# EFM32GG232F1024 register map
File version: 4.0.0
CPU: CM3 r2p1, little endian, MPU, no FPU, 3 interrupt priority bits
Registers are 32-bit, read-write, reset 0x0 unless marked. A register's access mark holds for its fields unless they carry their own. Offsets are from the block's base; [hi:lo] are bit positions; {n}, {i} and the like mark numbered series; 'fields as' and 'values as' point back to an identical list.

## GPIO
Base 0x40006000
0x00 PA_CTRL — Port Control Register
  [1:0] DRIVEMODE — Drive Mode Select
    0=STANDARD (6 mA drive current); 1=LOWEST (0.1 mA drive current); 2=HIGH (20 mA drive current); 3=LOW (1 mA drive current)
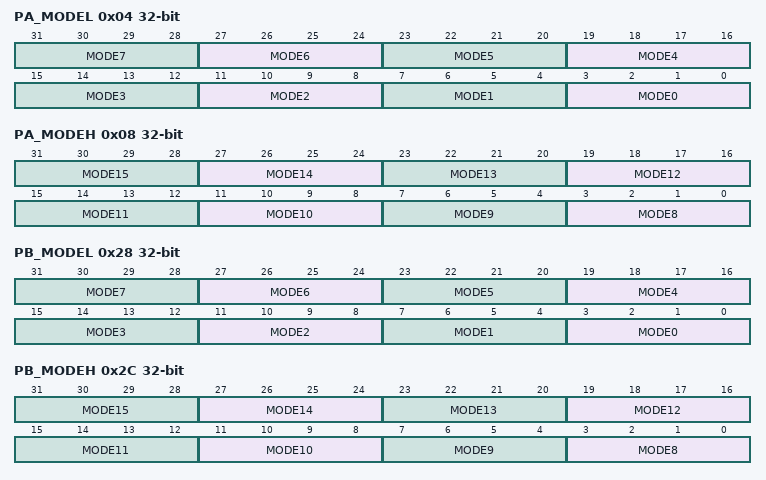
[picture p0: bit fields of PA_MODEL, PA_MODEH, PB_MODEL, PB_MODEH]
0x04 PA_MODEL — Port Pin Mode Low Register
  [all] fields
    0=DISABLED (Input disabled. Pullup if DOUT is set.); 1=INPUT (Input enabled. Filter if DOUT is set); 2=INPUTPULL (Input enabled. DOUT determines pull direction); 3=INPUTPULLFILTER (Input enabled with filter. DOUT determines pull direction); 4=PUSHPULL (Push-pull output); 5=PUSHPULLDRIVE (Push-pull output with drive-strength set by DRIVEMODE); 6=WIREDOR (Wired-or output); 7=WIREDORPULLDOWN (Wired-or output with pull-down); 8=WIREDAND (Open-drain output); 9=WIREDANDFILTER (Open-drain output with filter); 10=WIREDANDPULLUP (Open-drain output with pullup); 11=WIREDANDPULLUPFILTER (Open-drain output with filter and pullup); 12=WIREDANDDRIVE (Open-drain output with drive-strength set by DRIVEMODE); 13=WIREDANDDRIVEFILTER (Open-drain output with filter and drive-strength set by DRIVEMODE); 14=WIREDANDDRIVEPULLUP (Open-drain output with pullup and drive-strength set by DRIVEMODE); 15=WIREDANDDRIVEPULLUPFILTER (Open-drain output with filter, pullup and drive-strength set by DRIVEMODE)
  [4n+3:4n] MODE{n} (n=0..7) — Pin {n} Mode
0x08 PA_MODEH — Port Pin Mode High Register
  [all] fields
    values as the fields of PA_MODEL
  [4n-29:4n-32] MODE{n} (n=8..15) — Pin {n} Mode
0x0C PA_DOUT — Port Data Out Register
  [15:0] DOUT — Data Out
0x10 PA_DOUTSET wo — Port Data Out Set Register
  [15:0] DOUTSET — Data Out Set
0x14 PA_DOUTCLR wo — Port Data Out Clear Register
  [15:0] DOUTCLR — Data Out Clear
0x18 PA_DOUTTGL wo — Port Data Out Toggle Register
  [15:0] DOUTTGL — Data Out Toggle
0x1C PA_DIN ro — Port Data In Register
  [15:0] DIN — Data In
0x20 PA_PINLOCKN reset 0xFFFF — Port Unlocked Pins Register
  [15:0] PINLOCKN — Unlocked Pins
0x24 PB_CTRL — Port Control Register
  fields as PA_CTRL
0x28 PB_MODEL — Port Pin Mode Low Register
  fields as PA_MODEL
0x2C PB_MODEH — Port Pin Mode High Register
  fields as PA_MODEH
0x30 PB_DOUT — Port Data Out Register
  [15:0] DOUT — Data Out
0x34 PB_DOUTSET wo — Port Data Out Set Register
  [15:0] DOUTSET — Data Out Set
0x38 PB_DOUTCLR wo — Port Data Out Clear Register
  [15:0] DOUTCLR — Data Out Clear
0x3C PB_DOUTTGL wo — Port Data Out Toggle Register
  [15:0] DOUTTGL — Data Out Toggle
0x40 PB_DIN ro — Port Data In Register
  [15:0] DIN — Data In
0x44 PB_PINLOCKN reset 0xFFFF — Port Unlocked Pins Register
  [15:0] PINLOCKN — Unlocked Pins
0x48 PC_CTRL — Port Control Register
  fields as PA_CTRL
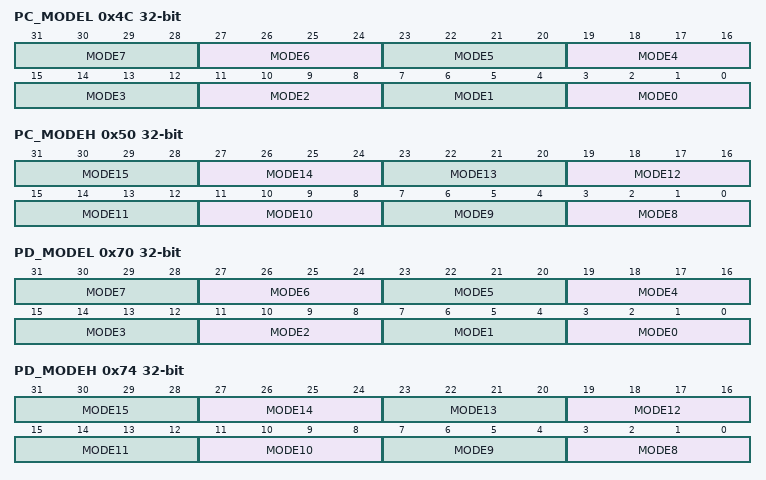
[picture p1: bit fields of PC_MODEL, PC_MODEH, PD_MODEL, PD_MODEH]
0x4C PC_MODEL — Port Pin Mode Low Register
  fields as PA_MODEL
0x50 PC_MODEH — Port Pin Mode High Register
  fields as PA_MODEH
0x54 PC_DOUT — Port Data Out Register
  [15:0] DOUT — Data Out
0x58 PC_DOUTSET wo — Port Data Out Set Register
  [15:0] DOUTSET — Data Out Set
0x5C PC_DOUTCLR wo — Port Data Out Clear Register
  [15:0] DOUTCLR — Data Out Clear
0x60 PC_DOUTTGL wo — Port Data Out Toggle Register
  [15:0] DOUTTGL — Data Out Toggle
0x64 PC_DIN ro — Port Data In Register
  [15:0] DIN — Data In
0x68 PC_PINLOCKN reset 0xFFFF — Port Unlocked Pins Register
  [15:0] PINLOCKN — Unlocked Pins
0x6C PD_CTRL — Port Control Register
  fields as PA_CTRL
0x70 PD_MODEL — Port Pin Mode Low Register
  fields as PA_MODEL
0x74 PD_MODEH — Port Pin Mode High Register
  fields as PA_MODEH
0x78 PD_DOUT — Port Data Out Register
  [15:0] DOUT — Data Out
0x7C PD_DOUTSET wo — Port Data Out Set Register
  [15:0] DOUTSET — Data Out Set
0x80 PD_DOUTCLR wo — Port Data Out Clear Register
  [15:0] DOUTCLR — Data Out Clear
0x84 PD_DOUTTGL wo — Port Data Out Toggle Register
  [15:0] DOUTTGL — Data Out Toggle
0x88 PD_DIN ro — Port Data In Register
  [15:0] DIN — Data In
0x8C PD_PINLOCKN reset 0xFFFF — Port Unlocked Pins Register
  [15:0] PINLOCKN — Unlocked Pins
0x90 PE_CTRL — Port Control Register
  fields as PA_CTRL
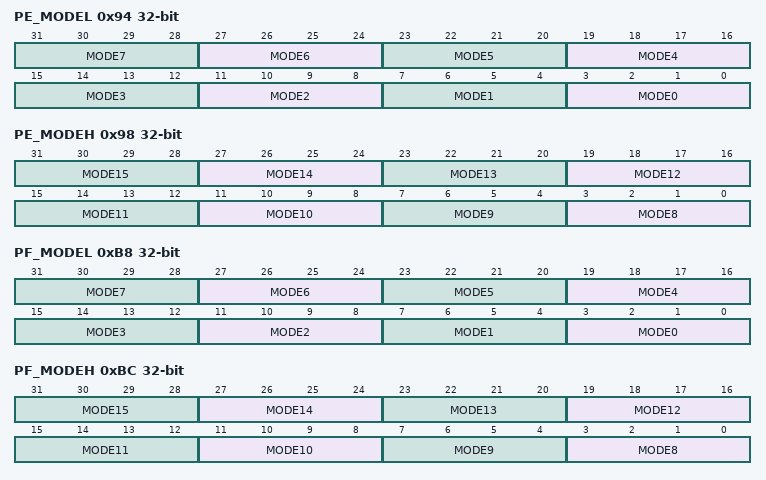
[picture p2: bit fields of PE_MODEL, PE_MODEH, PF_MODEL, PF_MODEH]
0x94 PE_MODEL — Port Pin Mode Low Register
  fields as PA_MODEL
0x98 PE_MODEH — Port Pin Mode High Register
  fields as PA_MODEH
0x9C PE_DOUT — Port Data Out Register
  [15:0] DOUT — Data Out
0xA0 PE_DOUTSET wo — Port Data Out Set Register
  [15:0] DOUTSET — Data Out Set
0xA4 PE_DOUTCLR wo — Port Data Out Clear Register
  [15:0] DOUTCLR — Data Out Clear
0xA8 PE_DOUTTGL wo — Port Data Out Toggle Register
  [15:0] DOUTTGL — Data Out Toggle
0xAC PE_DIN ro — Port Data In Register
  [15:0] DIN — Data In
0xB0 PE_PINLOCKN reset 0xFFFF — Port Unlocked Pins Register
  [15:0] PINLOCKN — Unlocked Pins
0xB4 PF_CTRL — Port Control Register
  fields as PA_CTRL
0xB8 PF_MODEL — Port Pin Mode Low Register
  fields as PA_MODEL
0xBC PF_MODEH — Port Pin Mode High Register
  fields as PA_MODEH
0xC0 PF_DOUT — Port Data Out Register
  [15:0] DOUT — Data Out
0xC4 PF_DOUTSET wo — Port Data Out Set Register
  [15:0] DOUTSET — Data Out Set
0xC8 PF_DOUTCLR wo — Port Data Out Clear Register
  [15:0] DOUTCLR — Data Out Clear
0xCC PF_DOUTTGL wo — Port Data Out Toggle Register
  [15:0] DOUTTGL — Data Out Toggle
0xD0 PF_DIN ro — Port Data In Register
  [15:0] DIN — Data In
0xD4 PF_PINLOCKN reset 0xFFFF — Port Unlocked Pins Register
  [15:0] PINLOCKN — Unlocked Pins
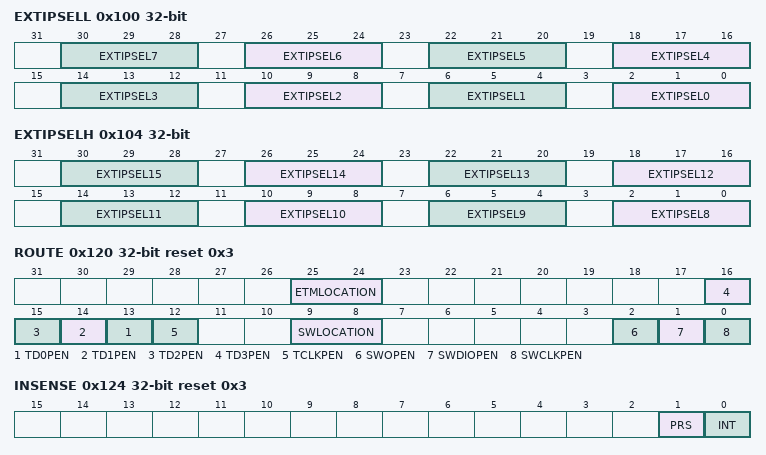
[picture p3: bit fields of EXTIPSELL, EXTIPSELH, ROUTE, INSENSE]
0x100 EXTIPSELL — External Interrupt Port Select Low Register
  [4n+2:4n] EXTIPSEL{n} (n=0..7) — External Interrupt {n} Port Select
    0=PORTA (Port A pin {n} selected for external interrupt {n}); 1=PORTB (Port B pin {n} selected for external interrupt {n}); 2=PORTC (Port C pin {n} selected for external interrupt {n}); 3=PORTD (Port D pin {n} selected for external interrupt {n}); 4=PORTE (Port E pin {n} selected for external interrupt {n}); 5=PORTF (Port F pin {n} selected for external interrupt {n})
0x104 EXTIPSELH — External Interrupt Port Select High Register
  [4n-30:4n-32] EXTIPSEL{n} (n=8..15) — External Interrupt {n} Port Select
    values as EXTIPSELL.EXTIPSEL0
0x108 EXTIRISE — External Interrupt Rising Edge Trigger Register
  [15:0] EXTIRISE — External Interrupt n Rising Edge Trigger Enable
0x10C EXTIFALL — External Interrupt Falling Edge Trigger Register
  [15:0] EXTIFALL — External Interrupt n Falling Edge Trigger Enable
0x110 IEN — Interrupt Enable Register
  [15:0] EXT — External Interrupt n Enable
0x114 IF ro — Interrupt Flag Register
  [15:0] EXT — External Interrupt Flag n
0x118 IFS wo — Interrupt Flag Set Register
  [15:0] EXT — External Interrupt Flag n Set
0x11C IFC wo — Interrupt Flag Clear Register
  [15:0] EXT — External Interrupt Flag Clear
0x120 ROUTE reset 0x3 — I/O Routing Register
  [25:24] ETMLOCATION — I/O Location
    {v}=LOC{v} (Location {v}) (v=0..3)
  [n+13] TD{n}PEN (n=0..3) — ETM Trace Data Pin Enable
  [12] TCLKPEN — ETM Trace Clock Pin Enable
  [9:8] SWLOCATION — I/O Location
    {v}=LOC{v} (Location {v}) (v=0..3)
  [2] SWOPEN — Serial Wire Viewer Output Pin Enable
  [1] SWDIOPEN — Serial Wire Data Pin Enable
  [0] SWCLKPEN — Serial Wire Clock Pin Enable
0x124 INSENSE reset 0x3 — Input Sense Register
  [1] PRS — PRS Sense Enable
  [0] INT — Interrupt Sense Enable
0x128 LOCK — Configuration Lock Register
  [15:0] LOCKKEY — Configuration Lock Key
    0=UNLOCKED; 1=LOCKED
0x12C CTRL — GPIO Control Register
  [0] EM4RET — Enable EM4 retention
0x130 CMD wo — GPIO Command Register
  [0] EM4WUCLR — EM4 Wake-up clear
0x134 EM4WUEN — EM4 Wake-up Enable Register
  [5:0] EM4WUEN — EM4 Wake-up enable
    1=A0 (Enable em4 wakeup on pin A0); 2=A6 (Enable em4 wakeup on pin A6); 4=C9 (Enable em4 wakeup on pin C9); 8=F1 (Enable em4 wakeup on pin F1); 16=F2 (Enable em4 wakeup on pin F2); 32=E13 (Enable em4 wakeup on pin E13)
0x138 EM4WUPOL — EM4 Wake-up Polarity Register
  [5:0] EM4WUPOL — EM4 Wake-up Polarity
    1=A0 (Determines polarity on pin A0); 2=A6 (Determines polarity on pin A6); 4=C9 (Determines polarity on pin C9); 8=F1 (Determines polarity on pin F1); 16=F2 (Determines polarity on pin F2); 32=E13 (Determines polarity on pin E13)
0x13C EM4WUCAUSE ro — EM4 Wake-up Cause Register
  [5:0] EM4WUCAUSE — EM4 wake-up cause
    1=A0 (This bit indicates an em4 wake-up request occurred on pin A0); 2=A6 (This bit indicates an em4 wake-up request occurred on pin A6); 4=C9 (This bit indicates an em4 wake-up request occurred on pin C9); 8=F1 (This bit indicates an em4 wake-up request occurred on pin F1); 16=F2 (This bit indicates an em4 wake-up request occurred on pin F2); 32=E13 (This bit indicates an em4 wake-up request occurred on pin E13)

## Notices in the file
# License
Copyright 2021 Silicon Laboratories Inc. www.silabs.com
SPDX-License-Identifier: Zlib
The licensor of this software is Silicon Laboratories Inc.
This software is provided 'as-is', without any express or implied
warranty. In no event will the authors be held liable for any damages
arising from the use of this software.
Permission is granted to anyone to use this software for any purpose,
including commercial applications, and to alter it and redistribute it
freely, subject to the following restrictions:
1. The origin of this software must not be misrepresented; you must not
claim that you wrote the original software. If you use this software
in a product, an acknowledgment in the product documentation would be
appreciated but is not required.
2. Altered source versions must be plainly marked as such, and must not be
misrepresented as being the original software.
3. This notice may not be removed or altered from any source distribution.
